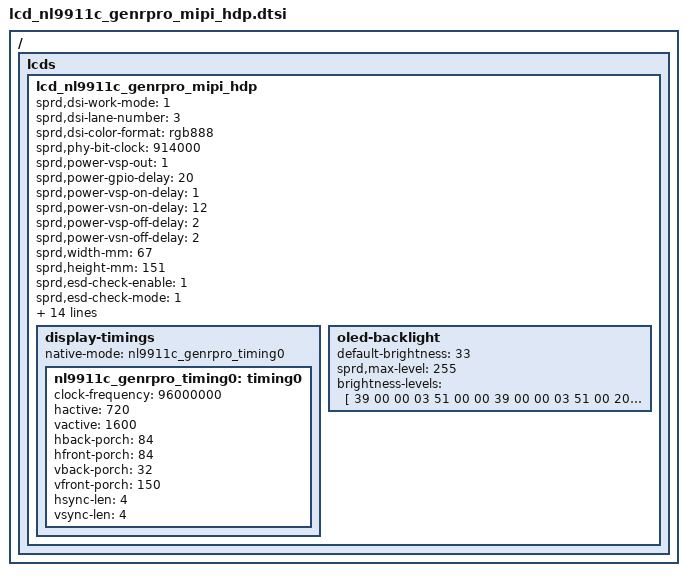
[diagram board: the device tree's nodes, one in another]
/*
 * nl9911c_  LCD config dtsi file for spreadtrum
 *
 * Copyright (C) 2018, Spreadtrum Communications Inc.
 *
 * SPDX-License-Identifier: (GPL-2.0+ OR MIT)
 */

/**
 *Name: lcd_nl9911c_genrpro_mipi_hdp.c
 *Author: LiChao
 *Date: 20210923
 *Purpose: nl9911c_genrpro lcd bringup
 */

/ {
    fragment {
        target-path = "/";
        __overlay__ {
            lcds {
                lcd_nl9911c_genrpro_mipi_hdp: lcd_nl9911c_genrpro_mipi_hdp {
                    sprd,dsi-work-mode = <1>; /* video burst mode*/
                    sprd,dsi-lane-number = <3>;
                    sprd,dsi-color-format = "rgb888";

                    sprd,phy-bit-clock = <914000>; /* kbps */
                    //sprd,phy-escape-clock = <20000>;/* kHz */
                    //sprd,dpi-clk-div = <1>;
                    sprd,power-vsp-out = <1>;
                    sprd,power-gpio-delay = <20>;/* ms */
                    sprd,power-vsp-on-delay = <1>;
                    sprd,power-vsn-on-delay = <12>;
                    sprd,power-vsp-off-delay = <2>;
                    sprd,power-vsn-off-delay = <2>;

                    sprd,width-mm = <67>;
                    sprd,height-mm = <151>;

                    sprd,esd-check-enable = <1>;
                    sprd,esd-check-mode = <1>;
                    sprd,esd-check-period = <2000>;
                    /* hs03 code for SL6215DEV-3924 by wenghailong at 2021/12/29 start */
                    sprd,dphy-taget-val = <5>; /*only nl9911c modify TA-GET value*/
                    /* hs03 code for SL6215DEV-3924 by wenghailong at 2021/12/29 end */
                    sprd,reset-on-sequence = <1 5>, <0 5>, <1 15>;
                    sprd,reset-off-sequence = <1 5>;
                    sprd,deep-sleep-in = <1>;

                    sprd,use-dcs-write;
                    sprd,initial-command = [
                        39 00 00 03 F0 5A 59
                        39 00 00 03 F1 A5 A6
                        39 00 00 21 B0 89 88 87 86 02 03 04 05 33 33 33 33 16 00 00 61 00 00 00 05 04 03 02 01 02 03 04 00 00 00 00 00
                        //OE=2us
                        39 00 00 21 B1 53 42 85 81 2C 00 00 77 00 00 04 08 54 00 00 00 44 40 02 01 40 02 01 40 02 01 40 02 01 00 00 00
                        39 00 00 12 B2 54 C4 82 05 40 02 01 40 02 01 05 05 54 0C 0C 0D 0B
                        39 00 00 21 B3 02 10 08 10 08 26 26 91 A2 33 44 00 26 00 18 01 02 08 20 30 0E 07 00 00 78 00 78 08 09 22 33 00
                        39 00 00 1D B4 43 1D E3 00 04 06 1C 22 10 12 0C 0E 43 43 43 43 43 43 43 43 43 43 FF FF FC 00 00 00
                        39 00 00 1D B5 43 1D E3 00 05 07 1C 22 11 13 0D 0F 43 43 43 43 43 43 43 43 43 43 FF FF FC 00 00 00
                        39 00 00 19 B8 00 00 00 00 00 00 00 00 00 00 00 00 00 00 00 00 00 00 00 00 00 00 00 00
                        //BB Power on sequence
                        39 00 00 0E BB 01 05 09 11 0D 19 1D 55 25 69 00 21 25
                        39 00 00 0F BC 00 00 00 00 02 20 FF 00 03 33 01 73 33 00
                        39 00 00 0B BD E9 02 4E CF 72 A4 08 44 AE 15
                        39 00 00 0B BE 68 7C 32 5A 0C 77 43 07 0E 0E
                        39 00 00 09 BF 07 25 07 25 7F 00 11 04
                        39 00 00 0A C0 10 FF FF FF FF FF 00 FF 00
                        39 00 00 14 C1 C0 20 20 96 04 54 54 04 2A 40 36 00 07 C0 10 FF 95 01 C0
                        39 00 00 07 C2 CC 01 10 00 01 30
                        39 00 00 0A C3 06 00 FF 00 FF 00 00 81 01
                        39 00 00 0B C4 84 01 2B 41 00 3C 00 03 03 2E
                        39 00 00 0C C5 03 1C C0 A0 80 10 42 44 08 0D 14
                        39 00 00 0B C6 87 A2 24 22 22 31 7F 04 08 00
                        39 00 00 17 C7 CA AF 9B 89 68 4D 22 77 40 12 E4 AF 03 D3 B5 88 6E 48 1A 7F E4 00
                        39 00 00 17 C8 CA AF 9B 89 68 4D 22 77 40 12 E4 AF 03 D3 B5 88 6E 48 1A 7F E4 00
                        39 00 00 02 CB 00
                        39 00 00 06 D0 80 0D FF 0F 61
                        39 00 00 02 D2 42
                        39 00 00 02 D7 DE
                        39 00 00 05 FE FF FF FF 40
                        39 00 00 1B E0 30 00 00 08 11 3F 22 62 DF A0 04 CC 01 FF F6 FF F0 FD FF FD F8 F5 FC FC FD FF
                        39 00 00 18 E1 EF FE FE FE FE EE F0 20 33 FF 00 00 6A 90 C0 0D 6A F0 3E FF 00 06 40
                        39 00 00 02 F6 3F
                        39 00 00 04 FA 45 93 01
                        39 00 00 03 F1 5A 59
                        39 00 00 03 F0 A5 A6
                        39 00 00 02 35 00
                        39 00 00 03 51 00 00
                        39 00 00 02 53 2C
                        39 00 00 02 55 00
                        39 78 00 01 11
                        39 05 00 01 29
                        39 00 00 02 26 01
                        ];

                    sprd,sleep-in-command = [
                        39 00 00 03 F0 5A 59
                        39 00 00 03 F1 A5 A6
                        39 01 00 02 26 08
                        39 14 00 01 28
                        39 6E 00 01 10
                        ];

                    sprd,sleep-out-command = [
                        39 78 00 01 11
                        39 32 00 01 29
                        39 00 00 02 26 01
                        ];

                    sprd,deep-sleep-in-command = [
                        39 00 00 03 F0 5A 59
                        39 00 00 03 F1 A5 A6
                        39 01 00 02 26 08
                        39 14 00 01 28
                        39 6E 00 01 10
                        39 00 00 02 CC 01
                    ];

                    display-timings {
                        native-mode = <&nl9911c_genrpro_timing0>;

                        nl9911c_genrpro_timing0: timing0 {
                            clock-frequency = <96000000>;
                            hactive = <720>;
                            vactive = <1600>;
                            hback-porch = <84>;
                            hfront-porch = <84>;
                            vback-porch = <32>;
                            vfront-porch = <150>;
                            hsync-len = <4>;
                            vsync-len = <4>;
                        };
                    };

                    oled-backlight {
                        default-brightness = <33>;
                        sprd,max-level = <255>;
                        brightness-levels = [
                            39 00 00 03 51 00 00
                            39 00 00 03 51 00 20
                            39 00 00 03 51 00 30
                            39 00 00 03 51 00 40
                            39 00 00 03 51 00 50
                            39 00 00 03 51 00 60
                            39 00 00 03 51 00 70
                            39 00 00 03 51 00 80
                            39 00 00 03 51 00 90
                            39 00 00 03 51 00 A0
                            39 00 00 03 51 00 B0
                            39 00 00 03 51 00 C0
                            39 00 00 03 51 00 D0
                            39 00 00 03 51 00 E0
                            39 00 00 03 51 00 F0
                            39 00 00 03 51 01 00
                            39 00 00 03 51 01 11
                            39 00 00 03 51 01 21
                            39 00 00 03 51 01 31
                            39 00 00 03 51 01 41
                            39 00 00 03 51 01 51
                            39 00 00 03 51 01 61
                            39 00 00 03 51 01 71
                            39 00 00 03 51 01 81
                            39 00 00 03 51 01 91
                            39 00 00 03 51 01 A1
                            39 00 00 03 51 01 B1
                            39 00 00 03 51 01 C1
                            39 00 00 03 51 01 D1
                            39 00 00 03 51 01 E1
                            39 00 00 03 51 01 F1
                            39 00 00 03 51 02 01
                            39 00 00 03 51 02 11
                            39 00 00 03 51 02 22
                            39 00 00 03 51 02 32
                            39 00 00 03 51 02 42
                            39 00 00 03 51 02 52
                            39 00 00 03 51 02 62
                            39 00 00 03 51 02 72
                            39 00 00 03 51 02 82
                            39 00 00 03 51 02 92
                            39 00 00 03 51 02 A2
                            39 00 00 03 51 02 B2
                            39 00 00 03 51 02 C2
                            39 00 00 03 51 02 D2
                            39 00 00 03 51 02 E2
                            39 00 00 03 51 02 F2
                            39 00 00 03 51 03 02
                            39 00 00 03 51 03 12
                            39 00 00 03 51 03 22
                            39 00 00 03 51 03 32
                            39 00 00 03 51 03 43
                            39 00 00 03 51 03 53
                            39 00 00 03 51 03 63
                            39 00 00 03 51 03 73
                            39 00 00 03 51 03 83
                            39 00 00 03 51 03 93
                            39 00 00 03 51 03 A3
                            39 00 00 03 51 03 B3
                            39 00 00 03 51 03 C3
                            39 00 00 03 51 03 D3
                            39 00 00 03 51 03 E3
                            39 00 00 03 51 03 F3
                            39 00 00 03 51 04 03
                            39 00 00 03 51 04 13
                            39 00 00 03 51 04 23
                            39 00 00 03 51 04 33
                            39 00 00 03 51 04 43
                            39 00 00 03 51 04 54
                            39 00 00 03 51 04 64
                            39 00 00 03 51 04 74
                            39 00 00 03 51 04 84
                            39 00 00 03 51 04 94
                            39 00 00 03 51 04 A4
                            39 00 00 03 51 04 B4
                            39 00 00 03 51 04 C4
                            39 00 00 03 51 04 D4
                            39 00 00 03 51 04 E4
                            39 00 00 03 51 04 F4
                            39 00 00 03 51 05 04
                            39 00 00 03 51 05 14
                            39 00 00 03 51 05 24
                            39 00 00 03 51 05 34
                            39 00 00 03 51 05 44
                            39 00 00 03 51 05 54
                            39 00 00 03 51 05 65
                            39 00 00 03 51 05 75
                            39 00 00 03 51 05 85
                            39 00 00 03 51 05 95
                            39 00 00 03 51 05 A5
                            39 00 00 03 51 05 B5
                            39 00 00 03 51 05 C5
                            39 00 00 03 51 05 D5
                            39 00 00 03 51 05 E5
                            39 00 00 03 51 05 F5
                            39 00 00 03 51 06 05
                            39 00 00 03 51 06 15
                            39 00 00 03 51 06 25
                            39 00 00 03 51 06 35
                            39 00 00 03 51 06 45
                            39 00 00 03 51 06 55
                            39 00 00 03 51 06 65
                            39 00 00 03 51 06 76
                            39 00 00 03 51 06 86
                            39 00 00 03 51 06 96
                            39 00 00 03 51 06 A6
                            39 00 00 03 51 06 B6
                            39 00 00 03 51 06 C6
                            39 00 00 03 51 06 D6
                            39 00 00 03 51 06 E6
                            39 00 00 03 51 06 F6
                            39 00 00 03 51 07 06
                            39 00 00 03 51 07 16
                            39 00 00 03 51 07 26
                            39 00 00 03 51 07 36
                            39 00 00 03 51 07 46
                            39 00 00 03 51 07 56
                            39 00 00 03 51 07 66
                            39 00 00 03 51 07 76
                            39 00 00 03 51 07 87
                            39 00 00 03 51 07 97
                            39 00 00 03 51 07 A7
                            39 00 00 03 51 07 B7
                            39 00 00 03 51 07 C7
                            39 00 00 03 51 07 D7
                            39 00 00 03 51 07 E7
                            39 00 00 03 51 07 F7
                            39 00 00 03 51 08 07
                            39 00 00 03 51 08 17
                            39 00 00 03 51 08 27
                            39 00 00 03 51 08 37
                            39 00 00 03 51 08 47
                            39 00 00 03 51 08 57
                            39 00 00 03 51 08 67
                            39 00 00 03 51 08 77
                            39 00 00 03 51 08 87
                            39 00 00 03 51 08 98
                            39 00 00 03 51 08 A8
                            39 00 00 03 51 08 B8
                            39 00 00 03 51 08 C8
                            39 00 00 03 51 08 D8
                            39 00 00 03 51 08 E8
                            39 00 00 03 51 08 F8
                            39 00 00 03 51 09 08
                            39 00 00 03 51 09 18
                            39 00 00 03 51 09 28
                            39 00 00 03 51 09 38
                            39 00 00 03 51 09 48
                            39 00 00 03 51 09 58
                            39 00 00 03 51 09 68
                            39 00 00 03 51 09 78
                            39 00 00 03 51 09 88
                            39 00 00 03 51 09 98
                            39 00 00 03 51 09 A9
                            39 00 00 03 51 09 B9
                            39 00 00 03 51 09 C9
                            39 00 00 03 51 09 D9
                            39 00 00 03 51 09 E9
                            39 00 00 03 51 09 F9
                            39 00 00 03 51 0A 09
                            39 00 00 03 51 0A 19
                            39 00 00 03 51 0A 29
                            39 00 00 03 51 0A 39
                            39 00 00 03 51 0A 49
                            39 00 00 03 51 0A 59
                            39 00 00 03 51 0A 69
                            39 00 00 03 51 0A 79
                            39 00 00 03 51 0A 89
                            39 00 00 03 51 0A 99
                            39 00 00 03 51 0A A9
                            39 00 00 03 51 0A BA
                            39 00 00 03 51 0A CA
                            39 00 00 03 51 0A DA
                            39 00 00 03 51 0A EA
                            39 00 00 03 51 0A FA
                            39 00 00 03 51 0B 0A
                            39 00 00 03 51 0B 1A
                            39 00 00 03 51 0B 2A
                            39 00 00 03 51 0B 3A
                            39 00 00 03 51 0B 4A
                            39 00 00 03 51 0B 5A
                            39 00 00 03 51 0B 6A
                            39 00 00 03 51 0B 7A
                            39 00 00 03 51 0B 8A
                            39 00 00 03 51 0B 9A
                            39 00 00 03 51 0B AA
                            39 00 00 03 51 0B BA
                            39 00 00 03 51 0B CB
                            39 00 00 03 51 0B DB
                            39 00 00 03 51 0B EB
                            39 00 00 03 51 0B FB
                            39 00 00 03 51 0C 0B
                            39 00 00 03 51 0C 1B
                            39 00 00 03 51 0C 2B
                            39 00 00 03 51 0C 3B
                            39 00 00 03 51 0C 4B
                            39 00 00 03 51 0C 5B
                            39 00 00 03 51 0C 6B
                            39 00 00 03 51 0C 7B
                            39 00 00 03 51 0C 8B
                            39 00 00 03 51 0C 9B
                            39 00 00 03 51 0C AB
                            39 00 00 03 51 0C BB
                            39 00 00 03 51 0C CB
                            39 00 00 03 51 0C DC
                            39 00 00 03 51 0C EC
                            39 00 00 03 51 0C FC
                            39 00 00 03 51 0D 0C
                            39 00 00 03 51 0D 1C
                            39 00 00 03 51 0D 2C
                            39 00 00 03 51 0D 3C
                            39 00 00 03 51 0D 4C
                            39 00 00 03 51 0D 5C
                            39 00 00 03 51 0D 6C
                            39 00 00 03 51 0D 7C
                            39 00 00 03 51 0D 8C
                            39 00 00 03 51 0D 9C
                            39 00 00 03 51 0D AC
                            39 00 00 03 51 0D BC
                            39 00 00 03 51 0D CC
                            39 00 00 03 51 0D DC
                            39 00 00 03 51 0D ED
                            39 00 00 03 51 0D FD
                            39 00 00 03 51 0E 0D
                            39 00 00 03 51 0E 1D
                            39 00 00 03 51 0E 2D
                            39 00 00 03 51 0E 3D
                            39 00 00 03 51 0E 4D
                            39 00 00 03 51 0E 5D
                            39 00 00 03 51 0E 6D
                            39 00 00 03 51 0E 7D
                            39 00 00 03 51 0E 8D
                            39 00 00 03 51 0E 9D
                            39 00 00 03 51 0E AD
                            39 00 00 03 51 0E BD
                            39 00 00 03 51 0E CD
                            39 00 00 03 51 0E DD
                            39 00 00 03 51 0E ED
                            39 00 00 03 51 0E FE
                            39 00 00 03 51 0F 0E
                            39 00 00 03 51 0F 1E
                            39 00 00 03 51 0F 2E
                            39 00 00 03 51 0F 3E
                            39 00 00 03 51 0F 4E
                            39 00 00 03 51 0F 5E
                            39 00 00 03 51 0F 6E
                            39 00 00 03 51 0F 7E
                            39 00 00 03 51 0F 8E
                            39 00 00 03 51 0F 9E
                            39 00 00 03 51 0F AE
                            39 00 00 03 51 0F BE
                            39 00 00 03 51 0F CE
                            39 00 00 03 51 0F DE
                            39 00 00 03 51 0F EE
                            39 00 00 03 51 0F FE
                            39 00 00 03 51 0F FE
                        ];
                    };
                };
            };
        };
    };
};
